# EOS-S3 register map
File version: 0.1
CPU: CM4 r0p1, selectable endian, MPU, FPU, 3 interrupt priority bits
Registers are 32-bit, read-write, reset 0x0 unless marked. A register's access mark holds for its fields unless they carry their own. Offsets are from the block's base; [hi:lo] are bit positions; {n}, {i} and the like mark numbered series; 'fields as' and 'values as' point back to an identical list.

## AIP — Analog IP block
Base 0x40005400
0x04 RTC_CTRL_1 — RTC control register 1
  [4:0] clkdiv — 5'b00000 : 32.768 Khz Please refer to the Technical Reference Manual for others (No SYNC Needed)
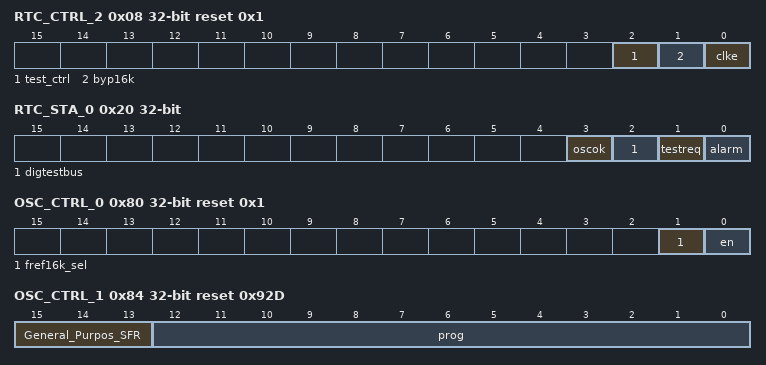
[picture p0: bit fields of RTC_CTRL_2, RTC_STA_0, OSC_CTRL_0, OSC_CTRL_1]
0x08 RTC_CTRL_2 reset 0x1 — RTC control register 2
  [2] test_ctrl — RTC Test[4:3] control for rtc bypass mode -- 0: Test[4:3] will be forced to 2'b11 when pad8 is strapped to 1, and forced to 2'b00 when pad8 is strapped to 0 , 1: normal mode; Test[4:0] controlled from 0x1C
  [1] byp16k — Changes internal clock division for 16384 Hz bypass compatibility -- 1'b0 : xtal is 32KHz - 1'b1 : xtal is 16KHz
  [0] clke — 1'b1 RTC Clock Output Enable (No SYNC Needed)
0x0C RTC_CTRL_3 — RTC control register 3
  [2:0] ce — 3'b000 Normal Function. Please refer to the Technical Reference Manual for detail
0x10 RTC_CTRL_4 — RTC Control register 4
  [0] wr — Write Pulse to program the RTC internal Register. Please refer to the Technical Reference Manual for detail
0x14 RTC_CTRL_5 — RTC control register 5
  [0] c — Serial Input clock
0x18 RTC_CTRL_6 — RTC control register 6
  [31:0] PI — Parallel Input data. Please refer to the Technical Reference Manual for detail
0x1C RTC_CTRL_7 — RTC control register 7
  [4:0] Test — Please refer to the Technical Reference Manual for detail
0x20 RTC_STA_0 ro — Incomplete information. Probably related to AIP RTC hardware status
  [3] oscok — Please refer to the Technical Reference Manual for detail, NO SYNC, FW need to read it twice to ensure the value.
  [2] digtestbus — Please refer to the Technical Reference Manual for detail, NO SYNC, FW need to read it twice to ensure the value.
  [1] testreq — Please refer to the Technical Reference Manual for detail, NO SYNC, FW need to read it twice to ensure the value.
  [0] alarm — Please refer to the Technical Reference Manual for detail, NO SYNC, FW need to read it twice to ensure the value.
0x24 RTC_STA_1 ro — Incomplete information. Probably related to AIP RTC hardware status
  [31:0] PO — Please refer to the Technical Reference Manual for detail, NO SYNC, FW need to read it twice to ensure the value.
0x80 OSC_CTRL_0 reset 0x1 — Oscilator control register 0
  [1] fref16k_sel — Reference clock selection
    0=with_32k_osc (Reference clock is 32KHz); 1=with_16k_osc (Reference clock is 16KHz)
  [0] en — 1'b0 : OSC OFF -- 1'b1 : OSC ON , (NO SYNC needed, OSC guarantee there is no Glitch)
    0=oscillator_off (Disable the oscillator); 1=oscillator_on (Enable the oscillator)
0x84 OSC_CTRL_1 reset 0x92D — Oscilator control register 1
  [15:13] General_Purpos_SFR — No description given
  [12:0] prog — Please refer to the Technical Reference Manual for others (No SYNC Needed). Power On Default Value is 76.97 MHz. No Support on 'Delta Mode'.
0x88 OSC_CTRL_2 — Oscilator control register 2
  [0] delta — Write 1, trigger delta mode, Note : This feature is NOT going to support, Keep it Low
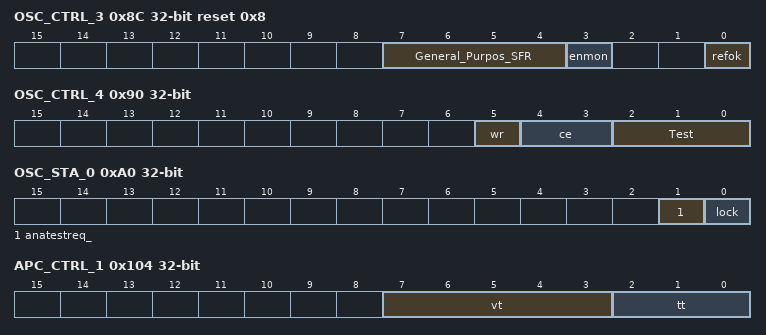
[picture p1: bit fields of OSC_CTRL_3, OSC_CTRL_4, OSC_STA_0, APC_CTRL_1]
0x8C OSC_CTRL_3 reset 0x8 — Oscilator control register 3
  [7:4] General_Purpos_SFR — No description given
  [3] enmon — Turn on Monitor function by default
  [0] refok — If 1'b1, will force the refok pin to 1, otherwise, it is control by the RTC/oscok
0x90 OSC_CTRL_4 — Oscilator control register 4
  [5] wr — Please refer to the Technical Reference Manual for detail
  [4:3] ce — Please refer to the Technical Reference Manual for detail
  [2:0] Test — Please refer to the Technical Reference Manual for detail
0x94 OSC_CTRL_5 — Oscilator control register 5
  [0] sdi — Please refer to the Technical Reference Manual for detail
0x98 OSC_CTRL_6 — Oscilator control register 6
  [0] sck — Please refer to the Technical Reference Manual for detail
0x9C OSC_CTRL_7 — Oscilator control register 7
0xA0 OSC_STA_0 ro — Contains information about oscilator status
  [1] anatestreq_ — Please refer to the Technical Reference Manual for detail, NO SYNC, FW need to read it twice to ensure the value.
  [0] lock — Please refer to the Technical Reference Manual for detail, NO SYNC, FW need to read it twice to ensure the value.
0xA4 OSC_STA_1 ro — Contains information about oscilator status
  [0] sdo — Please refer to the Technical Reference Manual for detail, NO SYNC, FW need to read it twice to ensure the value.
0x100 APC_CTRL_0 ro — APC control register 0
  [0] dis — 1'b0 : APC ON, Always ON
0x104 APC_CTRL_1 — APC control register 1
  [7:3] vt — Please refer to the Technical Reference Manual for others (No SYNC Needed)
  [2:0] tt — Please refer to the Technical Reference Manual for others (No SYNC Needed)
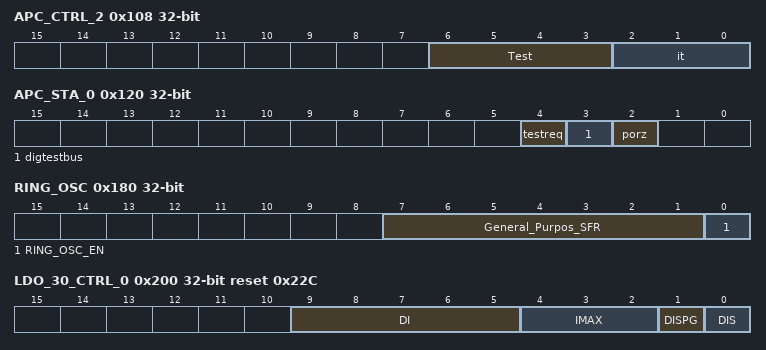
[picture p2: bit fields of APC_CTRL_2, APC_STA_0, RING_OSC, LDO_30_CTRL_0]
0x108 APC_CTRL_2 — APC control register 2
  [6:3] Test — Please refer to the Technical Reference Manual for others (No SYNC Needed)
  [2:0] it — Please refer to the Technical Reference Manual for others (No SYNC Needed)
{0x100+4i} APC_CTRL_{i} ro (i=3..7) — APC control register {i} // Reserved
0x120 APC_STA_0 ro — APC status register 0
  [4] testreq — Please refer to the Technical Reference Manual for detail, NO SYNC, FW need to read it twice to ensure the value.
  [3] digtestbus — Please refer to the Technical Reference Manual for detail, NO SYNC, FW need to read it twice to ensure the value.
  [2] porz — Please refer to the Technical Reference Manual for detail, NO SYNC, FW need to read it twice to ensure the value.
0x124 APC_STA_1 ro — APC status register 1
0x180 RING_OSC — Ring oscilator control register
  [7:1] General_Purpos_SFR — 1'b1 : Turn on the RING OSC, Ring OSC will be always on despite the HW control.
  [0] RING_OSC_EN — 1'b1 : Turn on the RING OSC, Ring OSC will be always on despite the HW control.
    0=oscillator_off (Disable the ring oscillator); 1=oscillator_on (Enable the ring oscillator)
0x200 LDO_30_CTRL_0 reset 0x22C — LDO_30 control register 0
  [9:5] DI — Output voltage programming. Note: Please keep LDO_30_DI and LDO_50_DI to be equal values for proper operation and lower power consumption.
    0=as_0_75v_output (Configures the LDO_30 output voltage as 0.75v); 1=as_0_77v_output (Configures the LDO_30 output voltage as 0.77v); 2=as_0_79v_output (Configures the LDO_30 output voltage as 0.79v); 3=as_0_81v_output (Configures the LDO_30 output voltage as 0.81v); 4=as_0_83v_output (Configures the LDO_30 output voltage as 0.83v); 5=as_0_85v_output (Configures the LDO_30 output voltage as 0.85v); 6=as_0_87v_output (Configures the LDO_30 output voltage as 0.87v); 7=as_0_89v_output (Configures the LDO_30 output voltage as 0.89v); 8=as_0_91v_output (Configures the LDO_30 output voltage as 0.91v); 9=as_0_93v_output (Configures the LDO_30 output voltage as 0.93v); 10=as_0_95v_output (Configures the LDO_30 output voltage as 0.95v); 11=as_0_97v_output (Configures the LDO_30 output voltage as 0.97v); 12=as_0_99v_output (Configures the LDO_30 output voltage as 0.99v); 13=as_1_01v_output (Configures the LDO_30 output voltage as 1.01v); 14=as_1_03v_output (Configures the LDO_30 output voltage as 1.03v); 15=as_1_05v_output (Configures the LDO_30 output voltage as 1.05v); 16=as_1_07v_output (Configures the LDO_30 output voltage as 1.07v); 17=as_1_09v_output (Configures the LDO_30 output voltage as 1.09v (default)); 18=as_1_11v_output (Configures the LDO_30 output voltage as 1.11v); 19=as_1_13v_output (Configures the LDO_30 output voltage as 1.13v); 20=as_1_15v_output (Configures the LDO_30 output voltage as 1.15v); 21=as_1_17v_output (Configures the LDO_30 output voltage as 1.17v); 22=as_1_19v_output (Configures the LDO_30 output voltage as 1.19v); 23=as_1_21v_output (Configures the LDO_30 output voltage as 1.21v)
  [4:2] IMAX — Configures the control for maximum expected current imax current (mA)
    0=max_30mA_current (Configure the maximum current for LDO_30 as 30mA); 1=max_18mA_current (Configure the maximum current for LDO_30 as 18mA); 2=max_12mA_current (Configure the maximum current for LDO_30 as 12mA); 3=max_7_2mA_current (Configure the maximum current for LDO_30 as 7.2mA (default)); 4=max_4_8mA_current (Configure the maximum current for LDO_30 as 4.8mA); 5=max_2_4mA_current (Configure the maximum current for LDO_30 as 2.4mA); 6=max_1_2mA_current (Configure the maximum current for LDO_30 as 1.2mA); 7=max_0_6mA_current (Configure the maximum current for LDO_30 as 0.6mA)
  [1] DISPG — Used to disable the power good comparator
  [0] DIS — Used to disable LDO_30
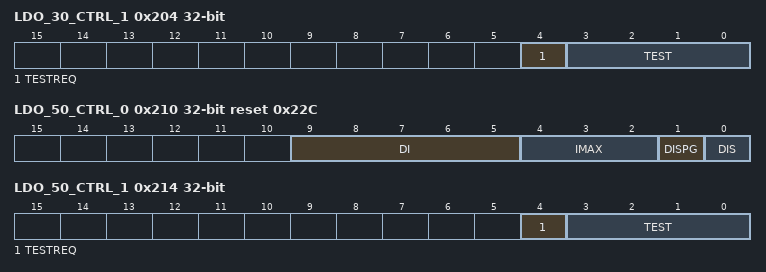
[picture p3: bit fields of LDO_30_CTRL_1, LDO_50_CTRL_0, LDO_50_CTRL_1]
0x204 LDO_30_CTRL_1 — LDO_30 control register 1
  [4] TESTREQ ro — Request of connection of the anatestbus to an external pin for characterization
  [3:0] TEST — Lab Test and internal block characterization Test control pins.
0x210 LDO_50_CTRL_0 reset 0x22C — LDO_50 control register 0
  fields as LDO_30_CTRL_0
0x214 LDO_50_CTRL_1 — LDO_50 control register 1
  fields as LDO_30_CTRL_1
